# PIC32CM6408PL10032 register map
Vendor: Microchip Technology; Series: PIC32CMPL10; File version: 0
CPU: CM0+ r0p0, little endian, no MPU, no FPU, VTOR, 2 interrupt priority bits, 15 interrupts
Registers are 32-bit, read-write, reset 0x0 unless marked. A register's access mark holds for its fields unless they carry their own. Offsets are from the block's base; [hi:lo] are bit positions.

## PAC — Peripheral Access Controller
Base 0x40000000
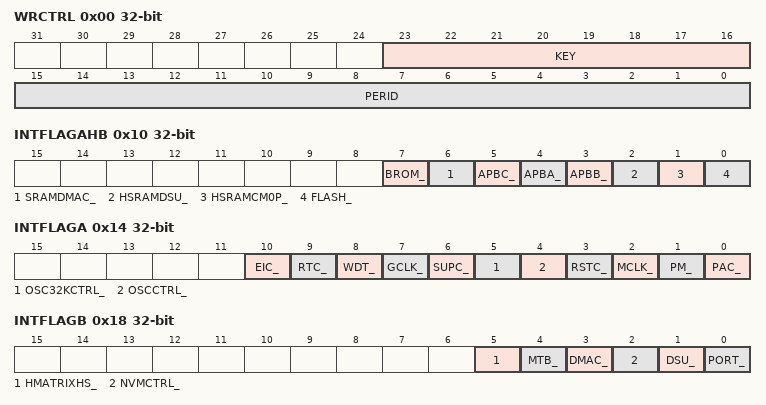
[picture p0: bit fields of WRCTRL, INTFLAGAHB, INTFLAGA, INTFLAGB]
0x00 WRCTRL — Write Control
  [23:16] KEY — Peripheral Access Control Key
    0=OFF (No action); 1=CLR (Clear the peripheral write-control); 2=SET (Set the peripheral write-control); 3=SETLCK (Set and lock the peripheral write-control until the next hardware reset)
  [15:0] PERID — Peripheral Identifier
    0=PAC (PAC - APBA Peripheral); 1=PM (PM - APBA Peripheral); 2=MCLK (MCLK - APBA Peripheral); 3=RSTC (RSTC - APBA Peripheral); 4=OSCCTRL (OSCCTRL - APBA Peripheral); 5=OSC32KCTRL (OSC32KCTRL - APBA Peripheral); 6=SUPC (SUPC - APBA Peripheral); 7=GCLK (GCLK - APBA Peripheral); 8=WDT (WDT - APBA Peripheral); 9=RTC (RTC - APBA Peripheral); 10=EIC (EIC - APBA Peripheral); 32=PORT (PORT - APBB Peripheral); 33=DSU (DSU - APBB Peripheral); 34=NVMCTRL (NVMCTRL - APBB Peripheral); 35=DMAC (DMAC - APBB Peripheral); 36=MTB (MTB - APBB Peripheral); 37=HMATRIXHS (HMATRIXHS - APBB Peripheral); 64=EVSYS (EVSYS - APBC Peripheral); 65=SERCOM0 (SERCOM0 - APBC Peripheral); 66=SERCOM1 (SERCOM1 - APBC Peripheral); 67=TC0 (TC0 - APBC Peripheral); 68=TC1 (TC1 - APBC Peripheral); 69=TC2 (TC2 - APBC Peripheral); 70=TCC0 (TCC0 - APBC Peripheral); 71=ADC0 (ADC0 - APBC Peripheral); 72=AC (AC - APBC Peripheral); 73=CCL (CCL - APBC Peripheral); 74=PTC (PTC - APBC Peripheral); 75=SYSCTRL (SYSCTRL - APBC Peripheral)
0x04 EVCTRL 8-bit — Event Control
  [0] ERREO — Peripheral Access Error Event Output
0x08 INTENCLR 8-bit write-1-clears — Interrupt Enable Clear
  [0] ERR — Peripheral Access Error Interrupt Disable
0x09 INTENSET 8-bit write-1-sets — Interrupt Enable Set
  [0] ERR — Peripheral Access Error Interrupt Enable
0x10 INTFLAGAHB write-1-clears — AHB Client Bus Interrupt Flag Status and Clear
  [7] BROM_, [6] SRAMDMAC_, [5] APBC_, [4] APBA_, [3] APBB_, [2] HSRAMDSU_, [1] HSRAMCM0P_, [0] FLASH_
0x14 INTFLAGA write-1-clears — Peripheral Interrupt Flag Status and Clear A
  [10] EIC_, [9] RTC_, [8] WDT_, [7] GCLK_, [6] SUPC_, [5] OSC32KCTRL_, [4] OSCCTRL_, [3] RSTC_, [2] MCLK_, [1] PM_, [0] PAC_
0x18 INTFLAGB write-1-clears — Peripheral Interrupt Flag Status and Clear B
  [5] HMATRIXHS_, [4] MTB_, [3] DMAC_, [2] NVMCTRL_, [1] DSU_, [0] PORT_
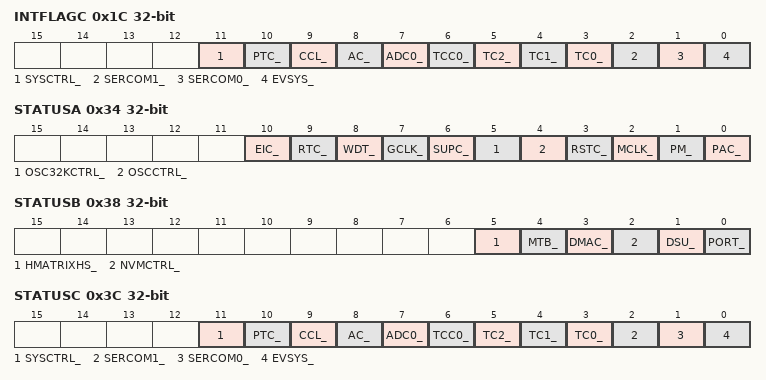
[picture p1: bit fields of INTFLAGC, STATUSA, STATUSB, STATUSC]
0x1C INTFLAGC write-1-clears — Peripheral Interrupt Flag Status and Clear C
  [11] SYSCTRL_, [10] PTC_, [9] CCL_, [8] AC_, [7] ADC0_, [6] TCC0_, [5] TC2_, [4] TC1_, [3] TC0_, [2] SERCOM1_, [1] SERCOM0_, [0] EVSYS_
0x34 STATUSA ro — Peripheral Write Protection Status A
  [10] EIC_ — EIC APB Protect Enable
  [9] RTC_ — RTC APB Protect Enable
  [8] WDT_ — WDT APB Protect Enable
  [7] GCLK_ — GCLK APB Protect Enable
  [6] SUPC_ — SUPC APB Protect Enable
  [5] OSC32KCTRL_ — OSC32KCTRL APB Protect Enable
  [4] OSCCTRL_ — OSCCTRL APB Protect Enable
  [3] RSTC_ — RSTC APB Protect Enable
  [2] MCLK_ — MCLK APB Protect Enable
  [1] PM_ — PM APB Protect Enable
  [0] PAC_ — PAC APB Protect Enable
0x38 STATUSB ro — Peripheral Write Protection Status B
  [5] HMATRIXHS_ — HMATRIXHS APB Protect Enable
  [4] MTB_ — MTB APB Protect Enable
  [3] DMAC_ — DMAC APB Protect Enable
  [2] NVMCTRL_ — NVMCTRL APB Protect Enable
  [1] DSU_ — DSU APB Protect Enable
  [0] PORT_ — PORT APB Protect Enable
0x3C STATUSC ro — Peripheral Write Protection Status C
  [11] SYSCTRL_ — SYSCTRL APB Protect Enable
  [10] PTC_ — PTC APB Protect Enable
  [9] CCL_ — CCL APB Protect Enable
  [8] AC_ — AC APB Protect Enable
  [7] ADC0_ — ADC0 APB Protect Enable
  [6] TCC0_ — TCC0 APB Protect Enable
  [5] TC2_ — TC2 APB Protect Enable
  [4] TC1_ — TC1 APB Protect Enable
  [3] TC0_ — TC0 APB Protect Enable
  [2] SERCOM1_ — SERCOM1 APB Protect Enable
  [1] SERCOM0_ — SERCOM0 APB Protect Enable
  [0] EVSYS_ — EVSYS APB Protect Enable
